# w600 register map
File version: v0.1
Registers are 32-bit, read-write, reset 0x0 unless marked. A register's access mark holds for its fields unless they carry their own. Offsets are from the block's base; [hi:lo] are bit positions.

## i2s
Base 0x40011A00
0x00 i2s control access per field reset 0x4800 — 控制I2S 相关功能，详见下述章节；
  [31:27] rsv ro
  [25:24] format rw — 数据格式选择
    0=I2S 数据格式 2’b01MSB Justified 数据格式 2’b10PCM A 声音数据格式; 3=PCM B 声音数据格式
  [14:12] rxth rw — RXFIFO 阙值…注意：当RXFIFO 中现有的字等于或者多于RXTH 的值时，RXTHIF 位会被置位。此时可以根据设置来选择触发RXDMA 或者 I2S 中断
    0=设置阙值为 0 个字; 0=设置阙值为 1 个字; 7=设置阙值为 7 个字
  [11:9] txth rw — TXFIFO 阙值…注意：当TXFIFO 中现有的字等于或者少于TXTH 的值时，TXTHIF 位会被置位。此时可以根据设置来选择触发TXDMA 或者I2S 中断
    0=设置阙值为 0 个字; 0=设置阙值为 1 个字; 7=设置阙值为 7 个字
  [7:6] rsv rw
  [5:4] wdwidth rw — 传输字长设置位
    0=字长 8 bit; 1=字长 16 bit; 2=字长 24 bit; 3=字长 32 bit
  [0] timeout_ctrl rw — 超时计数控制位，当此位被置 1 并且传输进程被主设备强制停止时，将不发生接收完成(RXDONE)中断
  [0] rxlch rw — 声道接收使能控制位注意：只有选择MONO_STEREO 的单声道模式时，此位才有效
    0=使能接收右声道数据; 1=使能接收左声道数据
  [0] mono_stereo rw — 单声道立体声选择位
    0=数据以立体声格式传输; 1=数据以单声道格式传输
  [0] rxdmaen rw — 接收DMA 请求使能位注意：当使能传输DMA 请求并且RXFIFO 中的字的个数等于或者大于RXTH时，I2S 控制器会向DMA 发出传输请求直至RXFIFO 为空才停止DMA 传输。
    0=不使能发送DMA 请求; 1=使能发送DMA 请求
  [0] txdmaen rw — 发送DMA 请求使能位注意：当使能传输 DMA 请求并且 TXFIFO 中的字的个数小于TXTH 时，I2S 控制器会向DMA 发出传输请求直至TXFIFO 满才停止DMA 传输。
    0=不使能发送DMA 请求; 1=使能发送DMA 请求
  [0] rxclr rw — 清空RXFIFO注意：写 1 清空RXFIFO，由硬件自动清空。读此位永远返回 0
    0=无效; 1=清空RXFIFO
  [0] txclr rw — 清空TXFIFO注意：写 1 清空TXFIFO，由硬件自动清空。读此位永远返回 0
    0=无效; 1=清空TXFIFO
  [0] lzcen rw — 左声道零交叉检测使能控制位
    0=停止左声道零交叉检测; 1=使能左声道零交叉检测
  [0] rzcen rw — 右声道零交叉检测使能控制位
    0=停止右声道零交叉检测; 1=使能右声道零交叉检测
  [0] rsv rw
  [0] clk_phase_sel rw — 选择时钟相位模式以上面提及的I2S 总线时序展示以上面提及的I2S 总线时序的反转形式展示
    0=默认模式; 1=反转模式
  [0] mute rw — 传输哑声使能标志位
    0=从移位寄存器传输数据，正常操作模式; 1=将传输数据置 0，使声音静音
  [0] rxen rw — 接收使能标志位
    0=停止I2S 数据接收; 1=使能I2S 数据接收
  [0] txen rw — 传输使能标志位
    0=停止I2S 数据传输; 1=使能I2S 数据传输
  [0] i2sen rw — I2S 使能标志位
    0=不使能; 1=使能
0x04 i2s_imask reset 0x3FF — 控制开启或关闭I2S 中所有的中断
  [31:10] rsv ro
  [0] lzcimask — 左声道零交叉中断使能标志位当使能中断，并且检测到左声道上有零交叉时，产生中断
    0=中断不使能; 1=中断使能
  [0] rzcimask — 右声道零交叉中断使能标志位当使能中断，并且检测到右声道上有零交叉时，产生中断
    0=中断不使能; 1=中断使能
  [0] txdonemask — 发送完成中断使能位当使能中断，并且TXFIFO 为空时，产生中断
    0=中断不使能; 1=中断使能
  [0] txthimask — TXFIFO 阙值中断使能位当使能中断，并且TXFIFO 中的数据数等于或者小于TXTH 时，产生中断
    0=中断不使能; 1=中断使能
  [0] txovimask — TXFIFO 溢出中断使能位注意：当使能中断，TXFIFO 满，CPU 再向TXFIFO 中写数据时，TXOVIF 标志位将会被置位
    0=中断不使能; 1=中断使能
  [0] txudimask — TXFIFO 下溢中断使能位注意：当使能TXFIFO 下溢中断，并且检测到TXUDIF 为 1 时，将产生下溢中断
    0=中断不使能; 1=中断使能
  [0] rxdonemask — 接收完成中断使能标志位当使能接收完成中断，并且接收过程完成时，将产生接收完成中断
    0=中断不使能; 1=中断使能
  [0] rxthimask — RXFIFO 阙值中断使能标志位当使能RXFIFO 阙值中断，并且 RXFIFO 中的数据个数等于或者多于阙值数时，产生生 RX 中断
    0=中断不使能; 1=中断使能
  [0] rxovimask — RXFIFO 溢出中断使能位注意：当使能RXFIFO 流出中断，并且检测到TXOVIF 为 1 时，将产生溢出中断
    0=中断不使能; 1=中断使能
  [0] rxudimask — RXFIFO 下溢中断使能位注意：当使能RXFIFO 下溢中断，并且检测到TXUDIF 为 1 时，将产生下溢中断
    0=中断不使能; 1=中断使能
0x08 i2s_int_flag access per field — 中断标志位，可用于查询中断是否产生及清除相关中断
  [31:13] rsv ro
  [0] txif ro — I2S 发送中断标志
    on read: 0=未发生I2S 中断; 1=I2S 有发送中断产生
  [0] rxif ro — I2S 接收中断标志
    on read: 0=未发生I2S 中断; 1=I2S 有接收中断产生
  [0] i2sif ro — I2S 中断标志位注意：只要 RX 或者 TX 之一有中断，此位就会置位
    on read: 0=未发生I2S 中断; 1=I2S 有中断产生
  [0] lzcif rw — 左声道零交叉检测标志此位指示左通道下一个样本数据符号位改变或所有数据位为零。注意：写 1 来清除中断标志
    0=未检测到零交叉; 1=检测到零交叉
  [0] rzcif rw — 右声道零交叉检测标志此位指示右通道下一个样本数据符号位改变或所有数据位为零。注意：写 1 来清除中断标志
    0=未检测到零交叉; 1=检测到零交叉
  [0] txdoneif rw — 发送完成中断标志注意：写 1 来清除中断标志
    0=本次发送未完成; 1=本次发送完成
  [0] txthif ro — RXFIFO 中断标志注意：当 TXFIFO 中字的个数(TXCNT)等于或者少于TXTH 设置的阙值时，这个位会被置 1，直至向 TXFIFO 中的写入数据并且 TXCNT 的值大于 TXTH 的值后，它才会变回 0。
    on read: 0=TXFIFO 中的字个数大于阙值; 1=TXFIFO 中的字个数小于或等于于阙值
  [0] txovif rw — TXFIFO 溢出中断标志
    0=TXFIFO 没有发生溢出中断; 1=TXFIFO 发生了溢出中断注意写 1 来清除中断标志
  [0] txudif rw — TXFIFO 下溢中断标志
    0=TXFIFO 没有发生下溢中断; 1=TXFIFO 发生了下溢中断注意写 1 来清除中断标志
  [0] rxdoneif rw — 接收完成中断标志注意：写 1 来清除中断标志
    0=本次接收未完成; 1=本次接收完成
  [0] rxthif ro — RXFIFO 中断标志注意：当 RXFIFO 中字的个数等于或者多于RXTH 设置的阙值时，这个位会被置 1，直至RXFIFO 中的数据被读出并且RXCNT 的值小于RXTH 的值后，它才会变回 0。
    on read: 0=RXFIFO 中的字个数小于阙值; 1=RXFIFO 中的字个数等于或大于阙值
  [0] rxovif rw — RXFIFO 溢出中断标志注意：写 1 来清除溢出中断
    0=RXFIFO 没有发生溢出中断; 1=RXFIFO 发生了溢出中断
  [0] rxudif rw — RXFIFO 下溢中断标志
    0=RXFIFO 没有发生下溢中断; 1=RXFIFO 发生了下溢中断注意写 1 来清除下溢中断
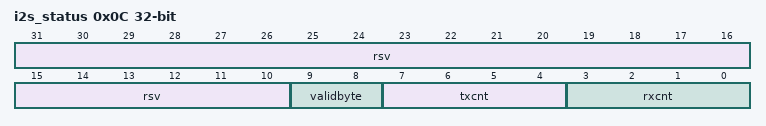
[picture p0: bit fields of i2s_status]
0x0C i2s_status ro — 用于查询 I2S 通信过程中 FIFO 的相关状态
  [31:10] rsv
  [9:8] validbyte — 最后一个字中可用的字节数。
    on read: 0=接收完成后，RXFIFO 中所有的字节都是可用的; 1=接收完成后，RXFIFO 中有 1 个字节是可用的; 2=接收完成后，RXFIFO 中有 2 个字节是可用的; 3=接收完成后，RXFIFO 中有 3 个字节是可用的
  [7:4] txcnt — 记录当前时刻TXFIFO 中字的个数。…
    on read: 0=没有数据; 1=有 1 个字; 8=有 8 个字
  [3:0] rxcnt — 记录当前时刻RXFIFO 中字的个数。…
    on read: 0=没有数据; 1=有 1 个字; 8=有 8 个字
0x10 i2s_tx — 控制器会将它里面的数据发送到总线上
  [31:0] txfifo — I2S 内置了8 个字长度的FIFO 用于存贮待发送的数据。每次向TXFIFO 中写一个字，TXFIFO 中的字就增加一个。I2S 控制器会自动将先进入TXFIFO 中的字发送出去。
0x14 i2s_rx ro — 控制器会将总线上的数据接收到它里面
  [31:0] rxfifo — I2S 内置了 8 个字长度的 FIFO 用于存贮接收到的数据。每次从 RXFIFO 中读取一个字，RXFIFO 中的字就会少一个。
